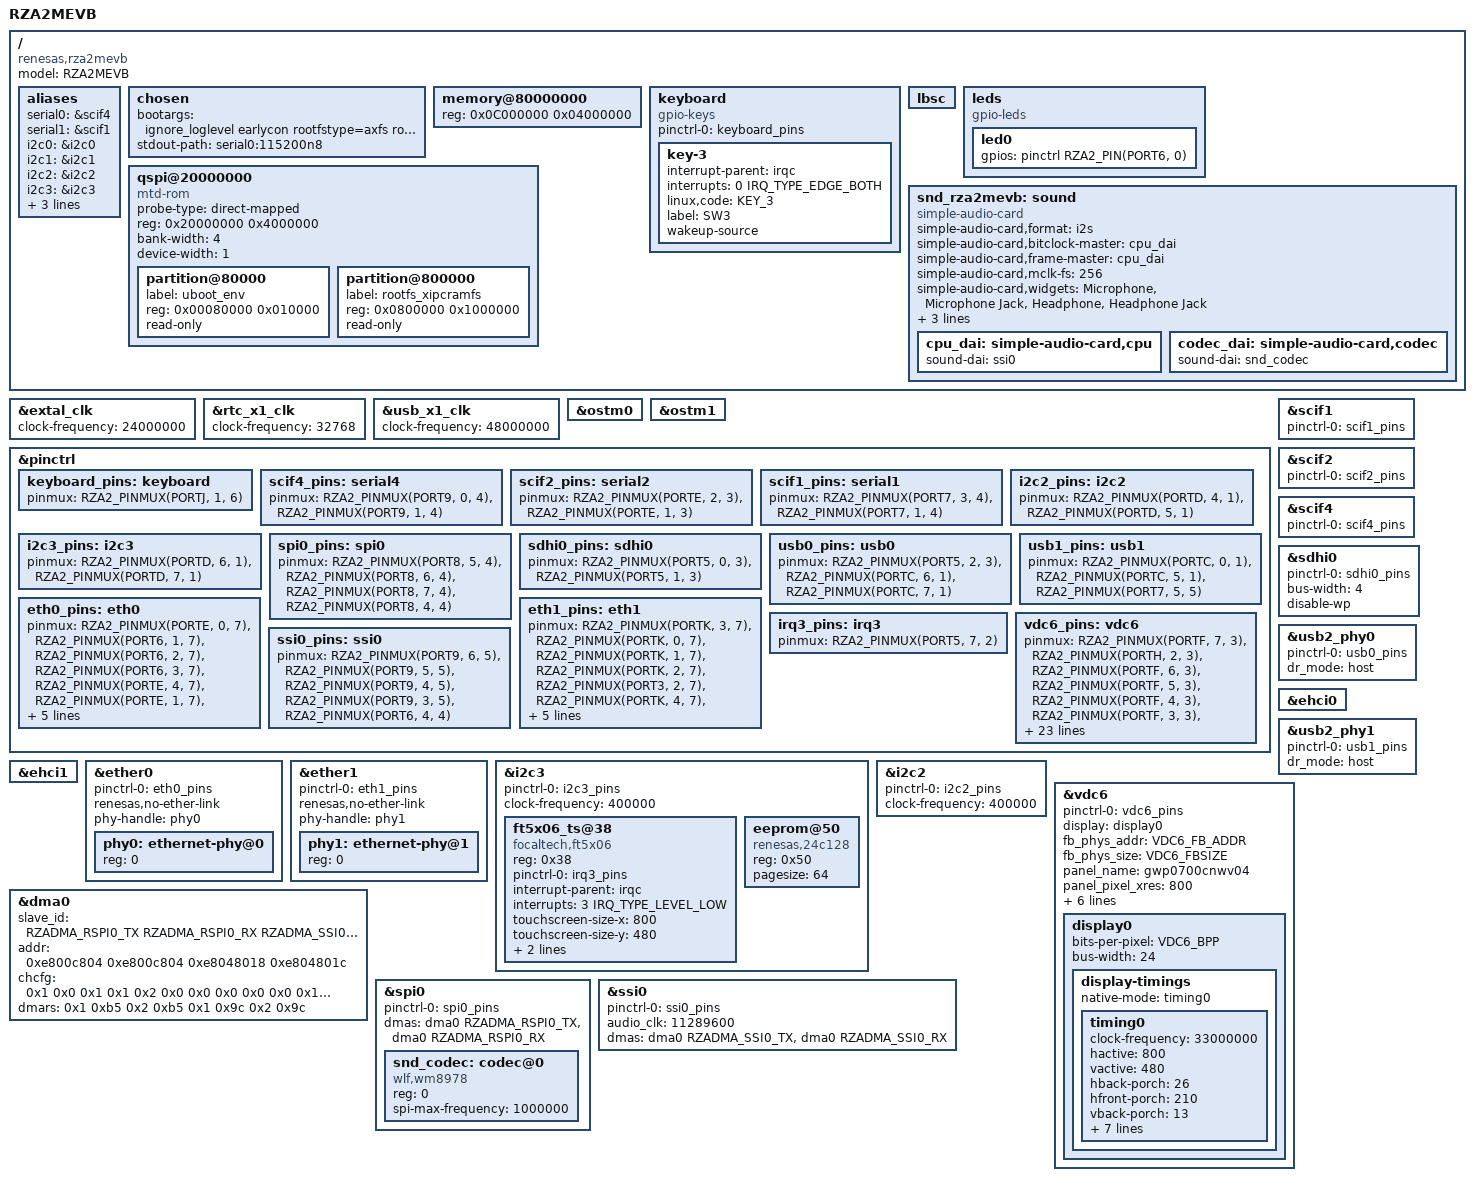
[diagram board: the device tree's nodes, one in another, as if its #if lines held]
// SPDX-License-Identifier: GPL-2.0 or MIT
/*
 * Device Tree Source for the RZA2MEVB board
 *
 * Copyright (C) 2018 Renesas Electronics
 *
 * This file is dual-licensed: you can use it either under the terms
 * of the GPL or the MIT license, at your option. Note that this dual
 * licensing only applies to this file, and not this project as a
 * whole.
 *
 */

/dts-v1/;
#include "r7s9210.dtsi"
#include <dt-bindings/gpio/gpio.h>
#include <dt-bindings/input/input.h>
#include <dt-bindings/pinctrl/r7s9210-pinctrl.h>

/* System Memory (must choose 1) */
//#define MEM_INTERNAL_RAM	/* Use 4MB Internal RAM as system memory */
#define MEM_HYPERRAM		/* Use external HyperRAM as system memory */
//#define MEM_SDRAM		/* Use external SDRAM as system memory */

/* Main serial console (must choose 1) */
#define CONSOLE 4		/* SCIF4 using CN5 (on-board USB-serial labeled "UART") */
//#define CONSOLE 2		/* SCIF2 using CN17 Header labeled "CMOS" */
//#define CONSOLE 1		/* SCIF1 using CN2 Header labeled "DRP" */

/* Additional serial connections (optional) */
//#define ADDITIONAL_SERIAL 2	/* SCIF2 as /dev/ttySC1 */
//#define ADDITIONAL_SERIAL 1	/* SCIF1 as /dev/ttySC1 */


/* Assign IDs to DMA channels (actual number is not important) */
#define RZADMA_SSI0_TX	1
#define RZADMA_SSI0_RX	2
#define RZADMA_RSPI0_TX	3
#define RZADMA_RSPI0_RX	4

/ {
	model = "RZA2MEVB";
	compatible = "renesas,rza2mevb", "renesas,r7s9210";

	aliases {
		/* It is recommended to always map the serial console as /dev/ttySC0
		 * in you system regardless of the actual SCIF channel used */
#if (CONSOLE == 1)
		serial0 = &scif1;
#elif (CONSOLE == 2)
		serial0 = &scif2;
#elif (CONSOLE == 4)
		serial0 = &scif4;
#endif

#if defined(ADDITIONAL_SERIAL)
#if (ADDITIONAL_SERIAL == 1)
		/* Force SCIF1 to show up as /dev/ttySC1 */
		serial1 = &scif1;
#elif (ADDITIONAL_SERIAL == 2)
		/* Force SCIF2 to show up as /dev/ttySC1 */
		serial1 = &scif2;
#endif
#endif

		/* These force channels to show up as specific device numbers */
		i2c0 = &i2c0;
		i2c1 = &i2c1;
		i2c2 = &i2c2;
		i2c3 = &i2c3;
		spi0 = &spi0;
		spi1 = &spi1;
		spi2 = &spi2;
	};

	chosen {
		/* Keep extra spaces at the end in case you want to add additional command line options from u-boot */
		bootargs = "ignore_loglevel earlycon rootfstype=axfs root=/dev/null rootflags=physaddr=0x20800000                   ";
		stdout-path = "serial0:115200n8";
	};

	memory@80000000 {
		device_type = "memory";
#ifdef MEM_INTERNAL_RAM
		reg = <0x80000000 0x00400000>;	 /* 4Mbyte of Internal RAM */
#endif
#ifdef MEM_HYPERRAM
		reg = <0x40000000 0x00800000>;	 /* 8Mbyte of External HyperRAM */
#endif
#ifdef MEM_SDRAM
		reg = <0x0C000000 0x04000000>;	 /* 64Mbyte of External SDRAM */
#endif
	};

	keyboard {
		compatible = "gpio-keys";

		pinctrl-names = "default";
		pinctrl-0 = <&keyboard_pins>;

		key-3 {
			interrupt-parent = <&irqc>;
			interrupts = <0 IRQ_TYPE_EDGE_BOTH>;
			linux,code = <KEY_3>;
			label = "SW3";
			wakeup-source;
		};
	};

	lbsc {
		#address-cells = <1>;
		#size-cells = <1>;
	};

#if 1 /* LED (GPIO) as an example */
	// echo 1 > /sys/devices/platform/leds/leds/led0/brightness
	// echo 0 > /sys/devices/platform/leds/leds/led0/brightness
	leds {
		status = "okay";
		compatible = "gpio-leds";

		led0 {
			gpios = <&pinctrl RZA2_PIN(PORT6, 0) GPIO_ACTIVE_HIGH>;	/* P6_0 */
		};
	};
#endif

#if 1 /* Read Only File system in QSPI Example */
	/* File System in XIP QSPI */
	/* Remember, we'll be in QSPI XIP mode at this point */
	/* Requires CONFIG_MTD_ROM=y */
	qspi@20000000 {
		compatible = "mtd-rom";
		//probe-type = "map_rom";
		probe-type = "direct-mapped";	// XIP from QSPI
		reg = <0x20000000 0x4000000>;	/* 64 MB*/
		bank-width = <4>;
		device-width = <1>;

		#address-cells = <1>;
		#size-cells = <1>;

		partition@80000 {
			label ="uboot_env";
			reg = <0x00080000 0x010000>; /* 64kB @ 0x20080000 */
			read-only;
		};
		partition@800000 {
			label ="rootfs_xipcramfs";
			reg = <0x0800000 0x1000000>; /* 16MB @ 0x20800000 */
			read-only;
		};
	};
#endif
};

/* EXTAL */
&extal_clk {
	clock-frequency = <24000000>;	/* 24MHz */
};

/* RTC_X1 (remove if not populated) */
&rtc_x1_clk {
	clock-frequency = <32768>;
};

/* USB_X1 */
&usb_x1_clk {
	clock-frequency = <48000000>;
};

/* High resolution System tick timers */
&ostm0 {
	status = "okay";
};

&ostm1 {
	status = "okay";
};

/*
 * Define your pin settings here
 *
 */
&pinctrl {

	keyboard_pins: keyboard {
		pinmux = <RZA2_PINMUX(PORTJ, 1, 6)>;	/* IRQ0 */
	};

	/* Serial Console */
	scif4_pins: serial4 {
		pinmux = <RZA2_PINMUX(PORT9, 0, 4)>,	/* TxD4 */
			 <RZA2_PINMUX(PORT9, 1, 4)>;	/* RxD4 */
	};

	/* Serial Console or additional serial */
	scif2_pins: serial2 {
		pinmux = <RZA2_PINMUX(PORTE, 2, 3)>,	/* TxD2 */
			 <RZA2_PINMUX(PORTE, 1, 3)>;	/* RxD2 */
	};

	/* Serial Console or additional serial */
	scif1_pins: serial1 {
		pinmux = <RZA2_PINMUX(PORT7, 3, 4)>,	/* TxD1 */
			 <RZA2_PINMUX(PORT7, 1, 4)>;	/* RxD1 */
	};

	/* RIIC ch2 (MIPI camera) */
	i2c2_pins: i2c2 {
		pinmux = <RZA2_PINMUX(PORTD, 4, 1)>,	/* RIIC2SCL */
			 <RZA2_PINMUX(PORTD, 5, 1)>;	/* RIIC2SDA */
	};

	/* RIIC ch3 (Touchscreen, EEPROM) */
	i2c3_pins: i2c3 {
		pinmux = <RZA2_PINMUX(PORTD, 6, 1)>,	/* RIIC3SCL */
			 <RZA2_PINMUX(PORTD, 7, 1)>;	/* RIIC3SDA */
	};

	/* RSPI ch3 (EEPROM, Audio codec) */
	spi0_pins: spi0 {
		pinmux = <RZA2_PINMUX(PORT8, 5, 4)>,	/* MISO0 */
			 <RZA2_PINMUX(PORT8, 6, 4)>,	/* MOSI0 */
			 <RZA2_PINMUX(PORT8, 7, 4)>,	/* CLK0 */
			 <RZA2_PINMUX(PORT8, 4, 4)>;	/* SSL0 */
	};

	/* SDHI 0 */
	sdhi0_pins: sdhi0 {
		pinmux = <RZA2_PINMUX(PORT5, 0, 3)>,	/* SD0_CD */
			 <RZA2_PINMUX(PORT5, 1, 3)>;	/* SD0_WP */
	};

	/* USB Channel 0 */
	usb0_pins: usb0 {
		pinmux = <RZA2_PINMUX(PORT5, 2, 3)>, /* VBUSIN0 */
			 <RZA2_PINMUX(PORTC, 6, 1)>, /* VBUSEN0 */
			 <RZA2_PINMUX(PORTC, 7, 1)>; /* OVRCUR0 */
	};

	/* USB Channel 1 */
	usb1_pins: usb1 {
		pinmux = <RZA2_PINMUX(PORTC, 0, 1)>, /* VBUSIN1 */
#if (CONSOLE == 4)
			 <RZA2_PINMUX(PORTC, 5, 1)>, /* VBUSEN1 */
			 <RZA2_PINMUX(PORT7, 5, 5)>; /* OVRCUR1 */
#else
			 <RZA2_PINMUX(PORTC, 5, 1)>; /* VBUSEN1 */
#endif
	};

	/* Ethernet - RMII mode */
	/* Channel 0 */
	eth0_pins: eth0 {
		pinmux = <RZA2_PINMUX(PORTE, 0, 7)>, /* REF50CK0 */
			 <RZA2_PINMUX(PORT6, 1, 7)>, /* RMMI0_TXDEN */
			 <RZA2_PINMUX(PORT6, 2, 7)>, /* RMII0_TXD0 */
			 <RZA2_PINMUX(PORT6, 3, 7)>, /* RMII0_TXD1 */
			 <RZA2_PINMUX(PORTE, 4, 7)>, /* RMII0_CRSDV */
			 <RZA2_PINMUX(PORTE, 1, 7)>, /* RMII0_RXD0 */
			 <RZA2_PINMUX(PORTE, 2, 7)>, /* RMII0_RXD1 */
			 <RZA2_PINMUX(PORTE, 3, 7)>, /* RMII0_RXER */
			 <RZA2_PINMUX(PORTE, 5, 1)>, /* ET0_MDC */
			 <RZA2_PINMUX(PORTE, 6, 1)>, /* ET0_MDIO */
			 <RZA2_PINMUX(PORTL, 0, 5)>; /* IRQ4 */
	};

	/* Ethernet - RMII mode */
	/* Channel 1 */
	eth1_pins: eth1 {
		pinmux = <RZA2_PINMUX(PORTK, 3, 7)>, /* REF50CK1 */
			 <RZA2_PINMUX(PORTK, 0, 7)>, /* RMMI1_TXDEN */
			 <RZA2_PINMUX(PORTK, 1, 7)>, /* RMII1_TXD0 */
			 <RZA2_PINMUX(PORTK, 2, 7)>, /* RMII1_TXD1 */
			 <RZA2_PINMUX(PORT3, 2, 7)>, /* RMII1_CRSDV */
			 <RZA2_PINMUX(PORTK, 4, 7)>, /* RMII1_RXD0 */
			 <RZA2_PINMUX(PORT3, 5, 7)>, /* RMII1_RXD1 */
			 <RZA2_PINMUX(PORT3, 1, 7)>, /* RMII1_RXER */
			 <RZA2_PINMUX(PORT3, 3, 1)>, /* ET1_MDC */
			 <RZA2_PINMUX(PORT3, 4, 1)>, /* ET1_MDIO */
			 <RZA2_PINMUX(PORTL, 1, 5)>; /* IRQ5 */
	};

	/* IRQ3 (Touchscreen) */
	irq3_pins: irq3 {
		pinmux = <RZA2_PINMUX(PORT5, 7, 2)>;	/* IRQ3 */
	};

	/* VDC LCD */
	vdc6_pins: vdc6 {
		pinmux =
#if 1 /* Parallel Interface */
			<RZA2_PINMUX(PORTF, 7, 3)>, // LCD0_DATA0
			<RZA2_PINMUX(PORTH, 2, 3)>, // LCD0_DATA1
			<RZA2_PINMUX(PORTF, 6, 3)>, // LCD0_DATA2
			<RZA2_PINMUX(PORTF, 5, 3)>, // LCD0_DATA3
			<RZA2_PINMUX(PORTF, 4, 3)>, // LCD0_DATA4
			<RZA2_PINMUX(PORTF, 3, 3)>, // LCD0_DATA5
			<RZA2_PINMUX(PORTF, 2, 3)>, // LCD0_DATA6
			<RZA2_PINMUX(PORTF, 1, 3)>, // LCD0_DATA7
			<RZA2_PINMUX(PORTF, 0, 3)>, // LCD0_DATA8
			<RZA2_PINMUX(PORT8, 0, 3)>, // LCD0_DATA9
			<RZA2_PINMUX(PORTA, 0, 3)>, // LCD0_DATA10
			<RZA2_PINMUX(PORTA, 1, 3)>, // LCD0_DATA11
			<RZA2_PINMUX(PORTA, 2, 3)>, // LCD0_DATA12
			<RZA2_PINMUX(PORTA, 3, 3)>, // LCD0_DATA13
			<RZA2_PINMUX(PORTA, 4, 3)>, // LCD0_DATA14
			<RZA2_PINMUX(PORTA, 5, 3)>, // LCD0_DATA15
			<RZA2_PINMUX(PORTA, 6, 3)>, // LCD0_DATA16
			<RZA2_PINMUX(PORTA, 7, 3)>, // LCD0_DATA17
			<RZA2_PINMUX(PORTB, 0, 3)>, // LCD0_DATA18
			<RZA2_PINMUX(PORTB, 1, 3)>, // LCD0_DATA19
			<RZA2_PINMUX(PORTB, 2, 3)>, // LCD0_DATA20
			<RZA2_PINMUX(PORTB, 3, 3)>, // LCD0_DATA21
			<RZA2_PINMUX(PORTB, 4, 3)>, // LCD0_DATA22
			<RZA2_PINMUX(PORTB, 5, 3)>, // LCD0_DATA23
			<RZA2_PINMUX(PORT7, 7, 3)>, // LCD0_TCON0
			<RZA2_PINMUX(PORT7, 6, 3)>, // LCD0_TCON1
		//	<RZA2_PINMUX(PORTC, 5, 5)>, // LCD0_TCON2	/* not used on this board */
			<RZA2_PINMUX(PORTC, 4, 5)>, // LCD0_TCON3
			<RZA2_PINMUX(PORTC, 3, 5)>, // LCD0_TCON4
		//	<RZA2_PINMUX(PORTC, 2, 5)>, // LCD0_TCON5	/* not used on this board */
		//	<RZA2_PINMUX(PORTC, 1, 5)>, // LCD0_TCON6	/* not used on this board */
			<RZA2_PINMUX(PORTJ, 6, 3)>; // LCD0_CLK
#else /* LVDS Interface  */
			<RZA2_PINMUX(PORT4, 0, 2)>, // TXOUT0P
			<RZA2_PINMUX(PORT4, 1, 2)>, // TXOUT0M
			<RZA2_PINMUX(PORT4, 2, 2)>, // TXOUT1P
			<RZA2_PINMUX(PORT4, 3, 2)>, // TXOUT1M
			<RZA2_PINMUX(PORT4, 4, 2)>, // TXOUT2P
			<RZA2_PINMUX(PORT4, 5, 2)>, // TXOUT2M
			<RZA2_PINMUX(PORT4, 6, 2)>, // TXCLKOUTP
			<RZA2_PINMUX(PORT4, 7, 2)>; // TXCLKOUTM
#endif
	};

	/* I2S Audio on SSI-0 */
	ssi0_pins: ssi0 {
		pinmux = <RZA2_PINMUX(PORT9, 6, 5)>,	/* SSIBCK0 */
			 <RZA2_PINMUX(PORT9, 5, 5)>,	/* SSILRCK0 */
			 <RZA2_PINMUX(PORT9, 4, 5)>,	/* SSITxD0 */
			 <RZA2_PINMUX(PORT9, 3, 5)>,	/* SSIRxD0 */
			 <RZA2_PINMUX(PORT6, 4, 4)>;	/* AUDIO_CLK */
	};
};

#if (CONSOLE == 1) || (ADDITIONAL_SERIAL == 1)
/* Serial Port */
/* Uses the "DRP" header, so requires SW6-1 = OFF
 * CN2-7 = DRP5/RxD1
 * CN2-8 = DRP6/TxD1
 * CN2-10 = GND
 *
 * When used as additional serial, run this to get a login in /dev/ttySC1
 *   $ su root -c "getty 115200 /dev/ttySC1 vt100" &
 *
 */
&scif1 {
	pinctrl-names = "default";
	pinctrl-0 = <&scif1_pins>;

	//uart-has-rtscts;	/* uncomment to use RTS/CTS, but you will also need to set up the pins */
	status = "okay";
};
#endif


#if (CONSOLE == 2) || (ADDITIONAL_SERIAL == 2)
/* Serial Port */
/* Uses the "CMOS" header, so requires SW6-4 = OFF
 * CN17-9 = RxD2
 * CN17-10 = TxD2
 * CN17-2 = GND
 *
 * When used as additional serial, run this to get a login in /dev/ttySC1
 *   $ su root -c "getty 115200 /dev/ttySC1 vt100" &
*/
&scif2 {
	pinctrl-names = "default";
	pinctrl-0 = <&scif2_pins>;

	//uart-has-rtscts;	/* uncomment to use RTS/CTS, but you will also need to set up the pins */
	status = "okay";
};
#endif

/* Serial Port */
/* Uses on board USB-serial convert labeled "UART" */
/* Requires SW6-3 = OFF */
#if (CONSOLE == 4)
&scif4 {
	pinctrl-names = "default";
	pinctrl-0 = <&scif4_pins>;

	//uart-has-rtscts;	/* uncomment to use RTS/CTS, but you will also need to set up the pins */
	status = "okay";
};
#endif

&sdhi0 {
        pinctrl-names = "default";
	pinctrl-0 = <&sdhi0_pins>;
        bus-width = <4>;
        status = "okay";
	disable-wp;
};


#if 1	/* USB-0 as Host */
	/* NOTE: Requires JP3 to be fitted */
&usb2_phy0 {
	pinctrl-names = "default";
	pinctrl-0 = <&usb0_pins>;
	dr_mode = "host";
	status = "okay";
};

&ehci0 {
	status = "okay";
};

#else	/* USB-0 as Device */
	/* NOTE: Requires JP3 to be open */
&usb2_phy0 {
	pinctrl-names = "default";
	pinctrl-0 = <&usb0_pins>;
	dr_mode = "peripheral";	/* Requires JP3 to be open */
	status = "okay";
};

&usbhs0 {
	status = "okay";
};
#endif

#if 1	/* USB-1 as Host */
&usb2_phy1 {
	pinctrl-names = "default";
	pinctrl-0 = <&usb1_pins>;
	dr_mode = "host";
	status = "okay";
};

&ehci1 {
	status = "okay";
};

#else	/* USB-1 as Device */
&usb2_phy1 {
	pinctrl-names = "default";
	pinctrl-0 = <&usb1_pins>;
	dr_mode = "peripheral";	/* Requires JP3 to be fitted */
	status = "okay";
};

&usbhs1 {
	status = "okay";
};
#endif

/* Make sure Ethernet 1 pins are usable (SW6-4 = ON) */
#if (CONSOLE != 1) && (ADDITIONAL_SERIAL != 1) && \
    (CONSOLE != 2) && (ADDITIONAL_SERIAL != 2)
&ether0 {
	pinctrl-names = "default";
	pinctrl-0 = <&eth0_pins>;
	status = "okay";
	renesas,no-ether-link;
	phy-handle = <&phy0>;
	phy0: ethernet-phy@0 {
		reg = <0>;
	};
};
#endif

&ether1 {
	pinctrl-names = "default";
	pinctrl-0 = <&eth1_pins>;
	status = "okay";
	renesas,no-ether-link;
	phy-handle = <&phy1>;
	phy1: ethernet-phy@1 {
		reg = <0>;
	};
};

/* RIIC3 (Touchscreen, EEPROM) */
&i2c3 {
	pinctrl-names = "default";
	pinctrl-0 = <&i2c3_pins>;

	status = "okay";
	clock-frequency = <400000>;

	ft5x06_ts@38 {
		compatible = "focaltech,ft5x06";
		reg = <0x38>;

		pinctrl-names = "default";
		pinctrl-0 = <&irq3_pins>;
		interrupt-parent = <&irqc>;
		interrupts = <3 IRQ_TYPE_LEVEL_LOW>;	/* IRQ3 */

		touchscreen-size-x = <800>;
		touchscreen-size-y = <480>;

		/* The touchscreen on the RSK LCD is backwards for some reason */
		touchscreen-inverted-x;
		touchscreen-inverted-y;
	};

	/* Renesas R1EX24128 EEPROM */
	/* 'eeprom' will show up under:
	 * /sys/bus/i2c/devices/3-0050/
	 */
        eeprom@50 {
                compatible = "renesas,24c128", "atmel,24c128";
                reg = <0x50>;
                pagesize = <64>;
        };
};

/* RIIC2 (MIPI Camera) */
&i2c2 {
	pinctrl-names = "default";
	pinctrl-0 = <&i2c2_pins>;

	status = "okay";
	clock-frequency = <400000>;
};

/* ========== LCD 24-bit Parallel Interface ========== */
#if 1

/* 800x480 RSK LCD - 24-bit Parallel Interface */

/* Pacer TFT LCD Panel, Model gwp0700cnwv04 */
#define XIP_KERNEL_WITHOUT_EXTERNAL_RAM 0
#if XIP_KERNEL_WITHOUT_EXTERNAL_RAM
  #define VDC6_BPP 16 /* 16bpp or 32bpp */
  #define VDC6_FBSIZE (480*272*VDC6_BPP/8)	/* Emulated WQVGA screen */
  #define VDC6_FB_ADDR 0	/* allocate memory at probe */
#else
  #define VDC6_BPP 16 /* 16bpp or 32bpp */
  #define VDC6_FBSIZE (800*480*VDC6_BPP/8)
  #define VDC6_FB_ADDR (0x80000000) /* fixed address in PAGE 0 */
#endif

/* VDC6 */
/* RSK LCD: 800x600 LCD */
/* Pacer TFT LCD Panel, Model gwp0700cnwv04 */
/* Parallel IF */
&vdc6 {
	pinctrl-names = "default";
	pinctrl-0 = <&vdc6_pins>;

	display = <&display0>;
	status = "okay";

	/* Set the physical frame buffer address for internal RAM. */
	fb_phys_addr = <VDC6_FB_ADDR>;
	fb_phys_size = <VDC6_FBSIZE>;

	panel_name = "gwp0700cnwv04";
	panel_pixel_xres = <800>;	/* panel native resolution */
	panel_pixel_yres = <480>;	/* panel native resolution */


	/* See 'drivers/video/fbdev/renesas/vdc5fb.h' for valid choices
	* for panel_icksel, panel_ocksel, and out_format */
	panel_icksel = <3>;	/* 3=ICKSEL_P1CLK (Peripheral clock 1) */
	panel_ocksel = <0>;	/* (don't care when lvds=0 ) */
	out_format = <0>;	/* 0=OUT_FORMAT_RGB888 */
	use_lvds = <0>;		/* Set to 0 or 1 */

	/* How are the TCON pins going to be used */
	tcon_sel = <
		0	/* TCON0:    0=TCON_SEL_STVA (VSYNC) */
		0xff	/* TCON1: 0xff=TCON_SEL_UNUSED */
		0xff	/* TCON2: 0xff=TCON_SEL_UNUSED */
		2	/* TCON3:    2=TCON_SEL_STH (HSYNC) */
		7	/* TCON4:    7=TCON_SEL_DE (DATA ENABLE) */
		0xff	/* TCON5: 0xff=TCON_SEL_UNUSED */
		0xff	/* TCON6: 0xff=TCON_SEL_UNUSED */
		>;

	display0: display0 {
		bits-per-pixel = <VDC6_BPP>;
		bus-width = <24>;

		display-timings {
			native-mode = <&timing0>;
			timing0: timing0 {
				clock-frequency = <33000000>; /* P1 clk / 2 */
#if XIP_KERNEL_WITHOUT_EXTERNAL_RAM
				hactive = <480>;
				vactive = <272>;
#else
				hactive = <800>;
				vactive = <480>;
#endif
				hback-porch = <26>;		/* back porch = 'HS Blanking'(46) - hsync-len(20) */
				hfront-porch = <210>;		/* 'HS Front Porch (210)' */
				vback-porch = <13>;		/* back porch = 'VS Blanking'(23) - vsync-len(10) */
				vfront-porch = <22>;		/* 'VS Front Porch(22)' */
				hsync-len = <20>;		/* pulse width of HSYNC (min=1, max=40) */
				vsync-len = <10>;		/* pulse width of VSYNC (min=1, max=20) */
				hsync-active = <1>; 		/* HSYNC pulse is: 0=Active LOW, 1=Active HIGH */
				vsync-active = <1>; 		/* VSYNC pulse is: 0=Active LOW, 1=Active HIGH */
				de-active = <0>; 		/* Data Enable signal is: 0=Active LOW , 1= Active HIGH */
				pixelclk-active = <0>; 		/* Pixel Data clocked on: 0=Negative clock edge */
			};
		};
	};
};
#endif /* Parallel LCD */


/* ========== LCD LVDS Interface Example ========== */
#if 0

/* LVDS Panel: HSD070PWW1 -B01 | 1280x800 (WXVGA), 7", LVDS, 16bpp */
/* LVDS IF */
#define VDC6_BPP 16
#define VDC6_FBSIZE (1280*800*VDC6_BPP/8)
#define VDC6_FB_ADDR (0x80000000) /* fixed address in PAGE 0 */

&vdc6 {
	pinctrl-names = "default";
	pinctrl-0 = <&vdc6_pins>;

	display = <&display0>;
	status = "okay";

	/* Set the physical frame buffer address for internal RAM. */
	fb_phys_addr = <VDC6_FB_ADDR>;
	fb_phys_size = <VDC6_FBSIZE>;

	panel_name = "HSD070PWW1";
	panel_pixel_xres = <1280>;	/* panel native resolution */
	panel_pixel_yres = <800>;	/* panel native resolution */

	/* See 'drivers/video/fbdev/renesas/vdc5fb.h' for valid choices
	* for panel_icksel, panel_ocksel, and out_format */
	panel_icksel = <0>;	/* (don't care when lvds=1) */
	panel_ocksel = <2>;	/* 2=OCKSEL_PLL_DIV7 (LVDS PLL clock divided by 7) */
	out_format = <0>;	/* 0=OUT_FORMAT_RGB888 */
	use_lvds = <1>;		/* Set to 0 or 1 */

	/* How are the TCON pins going to be used */
	tcon_sel = <
		0xff	/* TCON0: 0xff=TCON_SEL_UNUSED */
		0xff	/* TCON1: 0xff=TCON_SEL_UNUSED */
		0xff	/* TCON2: 0xff=TCON_SEL_UNUSED */
		7	/* TCON3:    7=TCON_SEL_DE (DATA ENABLE) */
		0xff	/* TCON4: 0xff=TCON_SEL_UNUSED */
		0xff	/* TCON5: 0xff=TCON_SEL_UNUSED */
		0xff	/* TCON6: 0xff=TCON_SEL_UNUSED */
		>;

	display0: display0 {
		bits-per-pixel = <VDC6_BPP>;		/* Set to 16 or 32 */
		bus-width = <16>;

		display-timings {
			native-mode = <&timing0>;
			timing0: timing0 {
				clock-frequency = <71100000>; /* min:64.3MHz, typ:71.1MHz, max:82MHz */
				hactive = <1280>;
				vactive = <800>;
				hback-porch = <16>;
				hfront-porch = <16>;
				vback-porch = <24>;
				vfront-porch = <1>;
				hsync-len = <136>; /* max */
				vsync-len = <3>; /* max */
				hsync-active = <1>; /* HIGH */
				vsync-active = <1>; /* HIGH */
				de-active = <0>; /* LOW */
				pixelclk-active = <0>; /* ??? */
			};
		};
	};
};
#endif /* LVDS */

/* ========== D/AVE 2D Example ========== */
/* Requires CONFIG_DAVE2D=y */
# if 0
&drw {
	/* vidmem:
	 * The D/AVE driver needs dedicated physical memory to hold things
	 * like rendering command buffers.
	 * Also, the memory defined by vidmem can be divided up and passed
	 * to the user application to be used as graphics buffers.
	 * See API functions d1_allocvidmem() and d1_freevidmem() in the
	 * DAVE2D driver.
	 *
	 * Remember, if you enabled 'double_buffer' in the VDC6 driver,
	 * twice as much memory will be allocated, so start your vidmem
	 * after that area.
	 *
	 * Note, the size must be a multiple of 1MB */
	vidmem = <0x80200000 0x100000>;

	status = "okay";
};

&vdc6 {

	/* Double Buffering. Reserves 2x memory space as frame buffer */
	/* Use "ioctl(fb0_fd, FBIOPAN_DISPLAY, &var)" from application
	 * space to change "var.yoffset=Y" where 'Y' is from 0 to var.yres
	 */
	double_buffer;	/* Uncomment for double buffering */
};
#endif

/* ========== SPI Flash MTD File System Example ========== */
#if 0

/* RSPI0 was tested by hooking up a SPI flash to DRP Header.
 * SW6-2: ON (to enable RSPI pin on DRP header)
 * Requires:
 *   CONFIG_MTD=y
 *   CONFIG_MTD_OF_PARTS=y
 *   CONFIG_MTD_M25P80=y
 *
 * After boot:
 * $ cat /proc/mtd
 * dev:    size   erasesize  name
 * mtd0: 00800000 04000000 "user"
 * mtd1: 00400000 00010000 "spi-data1"
 * mtd2: 00400000 00010000 "spi-data2"
 *
 * After that you should see some messages saying that your SPI flash has been
 * detected.
 * Then you can do things like erase and mount a JFFS2 file system:
 * $ flash_eraseall -j /dev/mtd1
 * $ mount -t jffs2 /dev/mtdblock1 /mnt
 */
&spi0 {
	pinctrl-names = "default";
	pinctrl-0 = <&spi0_pins>;
	status = "okay";

	flash@0 {
	/* 	compatible = "spansion,s25fl512s", "jedec,spi-nor"; */
		compatible = "jedec,spi-nor";	/* let it auto-detect the flash */

		reg = <0>;
		spi-max-frequency = <100000>;

		spi-cpol;
		spi-cpha;

		m25p,fast-read;

		partitions {
			compatible = "fixed-partitions";
			#address-cells = <1>;
			#size-cells = <1>;

			partition@0 {
				label = "spi-data1";
				reg = <0x00000000 0x00400000>;
				/* read-only; */
			};
			partition@40000 {
				label = "spi-data2";
				reg = <0x00400000 0x00400000>;
			};
		};
	};
};
#endif

/* ========== SPI EEPROM Example ========== */
#if 0

/* On early RZ/A2M CPU boards, a SPI EEPROM (R1EX25002ASA00G) was populated and
 * connect to RSPI-0. Note that these pins conflicted with SDRAM.
 *
 * In the kernel, enable CONFIG_EEPROM_AT25=y
 *
 * Will show up as /sys/class/spi_master/spi0/spi0.0/eeprom
 *
 * Testing:
 *  $ hexdump -C -n 16 /sys/class/spi_master/spi0/spi0.0/eeprom
 *  $ echo hello > /sys/class/spi_master/spi0/spi0.0/eeprom
 *  $ hexdump -C -n 16 /sys/class/spi_master/spi0/spi0.0/eeprom
 */
&spi0 {
	pinctrl-names = "default";
	pinctrl-0 = <&spi0_pins>;
	dmas = 	<&dma0 RZADMA_RSPI0_TX>,
			<&dma0 RZADMA_RSPI0_RX>;
	dma-names = "tx", "rx";
	status = "okay";

	eeprom@0 {
		compatible = "atmel,at25";	/* generic name */
		reg = <0>;
		spi-max-frequency = <1000000>;
		/* SPI Mode 3 */
		spi-cpol;
		spi-cpha;

		size = <256>;
		pagesize = <16>;
		address-width = <8>;
	};
};
#endif

/* ================ AUDIO EXAMPLE ================ */
#ifndef MEM_SDRAM
	/* Requires SW6-2 to be 'OFF' */

	/* NOTE: The RSPI-0 channel to the codec is using the same pins
	 * as the SDRAM A4,A6,A7 pins, so audio cannot be used at the
	 * same time as SDRAM. */

/* DMA Configuration */
&dma0  {
	/* Assign Slave IDs */
	slave_id = <RZADMA_RSPI0_TX
		    RZADMA_RSPI0_RX
		    RZADMA_SSI0_TX
		    RZADMA_SSI0_RX>;
	/* Address of data source/destination */
	addr = <0xe800c804	/* SPDR_0 */
		0xe800c804	/* SPDR_0 */
		0xe8048018	/* SSIFTDR_0 */
		0xe804801c	/* SSIFRDR_0 */
		>;
	/* Channel Configuration Register (CHCFG) for slave device */
	/* .reqd .loen .hien .lvl .am .sds .dds .tm */
	chcfg = <0x1 0x0 0x1 0x1 0x2 0x0 0x0 0x0	/* RSPI0_TX (req sig=SPDR0) */
		 0x0 0x0 0x1 0x1 0x2 0x0 0x0 0x0	/* RSPI0_RX (req sig=SPDR0) */
		 0x1 0x0 0x1 0x0 0x2 0x1 0x1 0x0	/* SSI ch0 TX (req sig=SSIFTDR_0) */
		 0x0 0x0 0x1 0x0 0x2 0x1 0x1 0x0	/* SSI ch0 RX (req sig=SSIFRDR_0) */
		 >;
	/* DMARS for slave device */
	/* .rid .mid */
	dmars = <0x1 0xb5	/* RSPI0_TX */
		 0x2 0xb5	/* RSPI0_RX */
		 0x1 0x9c	/* SSI ch0 TX */
		 0x2 0x9c	/* SSI ch0 RX */
		 >;
};

/* Audio codec (control) is connected to RSPI-0 */
&spi0 {
	pinctrl-names = "default";
	pinctrl-0 = <&spi0_pins>;
	status = "okay";

#if 1 /* DMA */
	/* DMA is not required for the SPI interface, and is actually
	 * not used because the transfers are so small. It is being
	 * used here just as another example of using DMA on multiple
	 * peripherals */
	dmas = <&dma0 RZADMA_RSPI0_TX>,
	       <&dma0 RZADMA_RSPI0_RX>;
	dma-names = "tx", "rx";
#endif

	snd_codec: codec@0 {
		#sound-dai-cells = <0>;
		compatible = "wlf,wm8978";
		reg = <0>;
		spi-max-frequency = <1000000>;	/* ~5 MHz */
	};
};

/* Audio codec (I2S data) is connected to SSI-0 */
&ssi0 {
	pinctrl-names = "default";
	pinctrl-0 = <&ssi0_pins>;
	status = "okay";
	audio_clk = <11289600>;

#if 1 /* DMA */
	/* The SSI driver can be using without DMA, but it is not
	 * recommended because when the system is loaded, you will get
	 * many buffer underruns/overruns. */
	dmas = <&dma0 RZADMA_SSI0_TX>,
	       <&dma0 RZADMA_SSI0_RX>;
	dma-names = "tx", "rx";
#endif
};

/ {
	/* Simple Audio Card (must be a root node) */
	snd_rza2mevb: sound {
		compatible = "simple-audio-card";
		simple-audio-card,format = "i2s";
		simple-audio-card,bitclock-master = <&cpu_dai>;
		simple-audio-card,frame-master = <&cpu_dai>;
		simple-audio-card,mclk-fs = <256>;
		simple-audio-card,widgets =
			"Microphone", "Microphone Jack",	/* "MIC" is really an AUX input */
			"Headphone", "Headphone Jack";		/* "HP" output */
		simple-audio-card,routing =
			"L2", "Microphone Jack",	/* (L2) Left Input Mixer */
			"R2", "Microphone Jack",	/* (R2) Right Input Mixer */
			"Headphone Jack", "LHP",	/* (LOUT1) Left Headphone Out */
			"Headphone Jack", "RHP";	/* (ROUT1) Right Headphone Out */

		cpu_dai: simple-audio-card,cpu {
			sound-dai = <&ssi0>;
		};

		codec_dai: simple-audio-card,codec {
			sound-dai = <&snd_codec>;
		};
	};
};
#endif /* AUDIO EXAMPLE */
